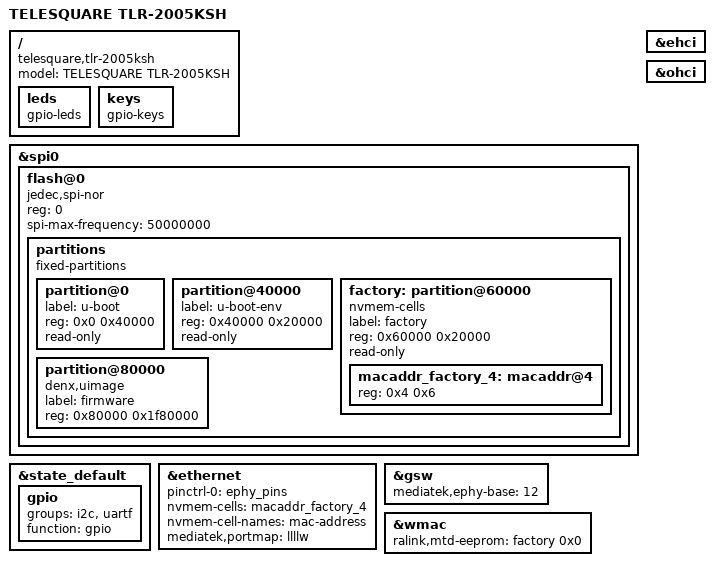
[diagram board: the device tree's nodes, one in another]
// SPDX-License-Identifier: GPL-2.0-or-later OR MIT

#include "mt7620a.dtsi"

#include <dt-bindings/gpio/gpio.h>
#include <dt-bindings/input/input.h>

/ {
	compatible = "telesquare,tlr-2005ksh", "ralink,mt7620a-soc";
	model = "TELESQUARE TLR-2005KSH";

	leds {
		compatible = "gpio-leds";
	};

	keys {
		compatible = "gpio-keys";
	};
};

&spi0 {
	status = "okay";

	flash@0 {
		compatible = "jedec,spi-nor";
		reg = <0>;
		spi-max-frequency = <50000000>;

		partitions {
			compatible = "fixed-partitions";
			#address-cells = <1>;
			#size-cells = <1>;

			partition@0 {
				label = "u-boot";
				reg = <0x0 0x40000>;
				read-only;
			};

			partition@40000 {
				label = "u-boot-env";
				reg = <0x40000 0x20000>;
				read-only;
			};

			factory: partition@60000 {
				label = "factory";
				reg = <0x60000 0x20000>;
				read-only;
			};

			partition@80000 {
				compatible = "denx,uimage";
				label = "firmware";
				reg = <0x80000 0x1f80000>;
			};
		};
	};
};

&state_default {
	gpio {
		groups = "i2c", "uartf";
		function = "gpio";
	};
};

&ethernet {
	pinctrl-names = "default";
	pinctrl-0 = <&ephy_pins>;

	nvmem-cells = <&macaddr_factory_4>;
	nvmem-cell-names = "mac-address";

	mediatek,portmap = "llllw";
};

&gsw {
	mediatek,ephy-base = /bits/ 8 <12>;
};

&ehci {
	status = "okay";
};

&ohci {
	status = "okay";
};

&wmac {
	ralink,mtd-eeprom = <&factory 0x0>;
};

&factory {
	compatible = "nvmem-cells";
	#address-cells = <1>;
	#size-cells = <1>;

	macaddr_factory_4: macaddr@4 {
		reg = <0x4 0x6>;
	};
};
